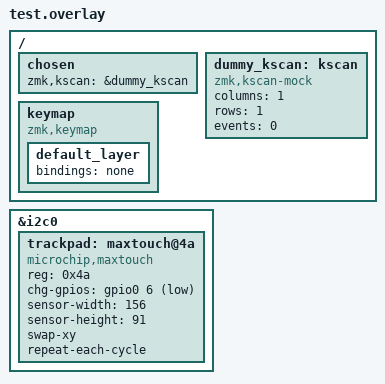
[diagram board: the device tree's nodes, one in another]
/*
 * Minimal test overlay to validate Devicetree binding and driver compilation
 */

#include <dt-bindings/zmk/keys.h>
#include <behaviors.dtsi>

/ {
    chosen {
        zmk,kscan = &dummy_kscan;
    };

    dummy_kscan: kscan {
        compatible = "zmk,kscan-mock";
        columns = <1>;
        rows = <1>;
        events = <0>;
    };

    keymap {
        compatible = "zmk,keymap";
        default_layer {
            bindings = <&none>;
        };
    };
};

&i2c0 {
    status = "okay";

    trackpad: maxtouch@4a {
        compatible = "microchip,maxtouch";
        reg = <0x4a>;
        chg-gpios = <&gpio0 6 (GPIO_ACTIVE_LOW | GPIO_PULL_UP)>;
        sensor-width = <156>;
        sensor-height = <91>;
        swap-xy;
        repeat-each-cycle;
    };
};
